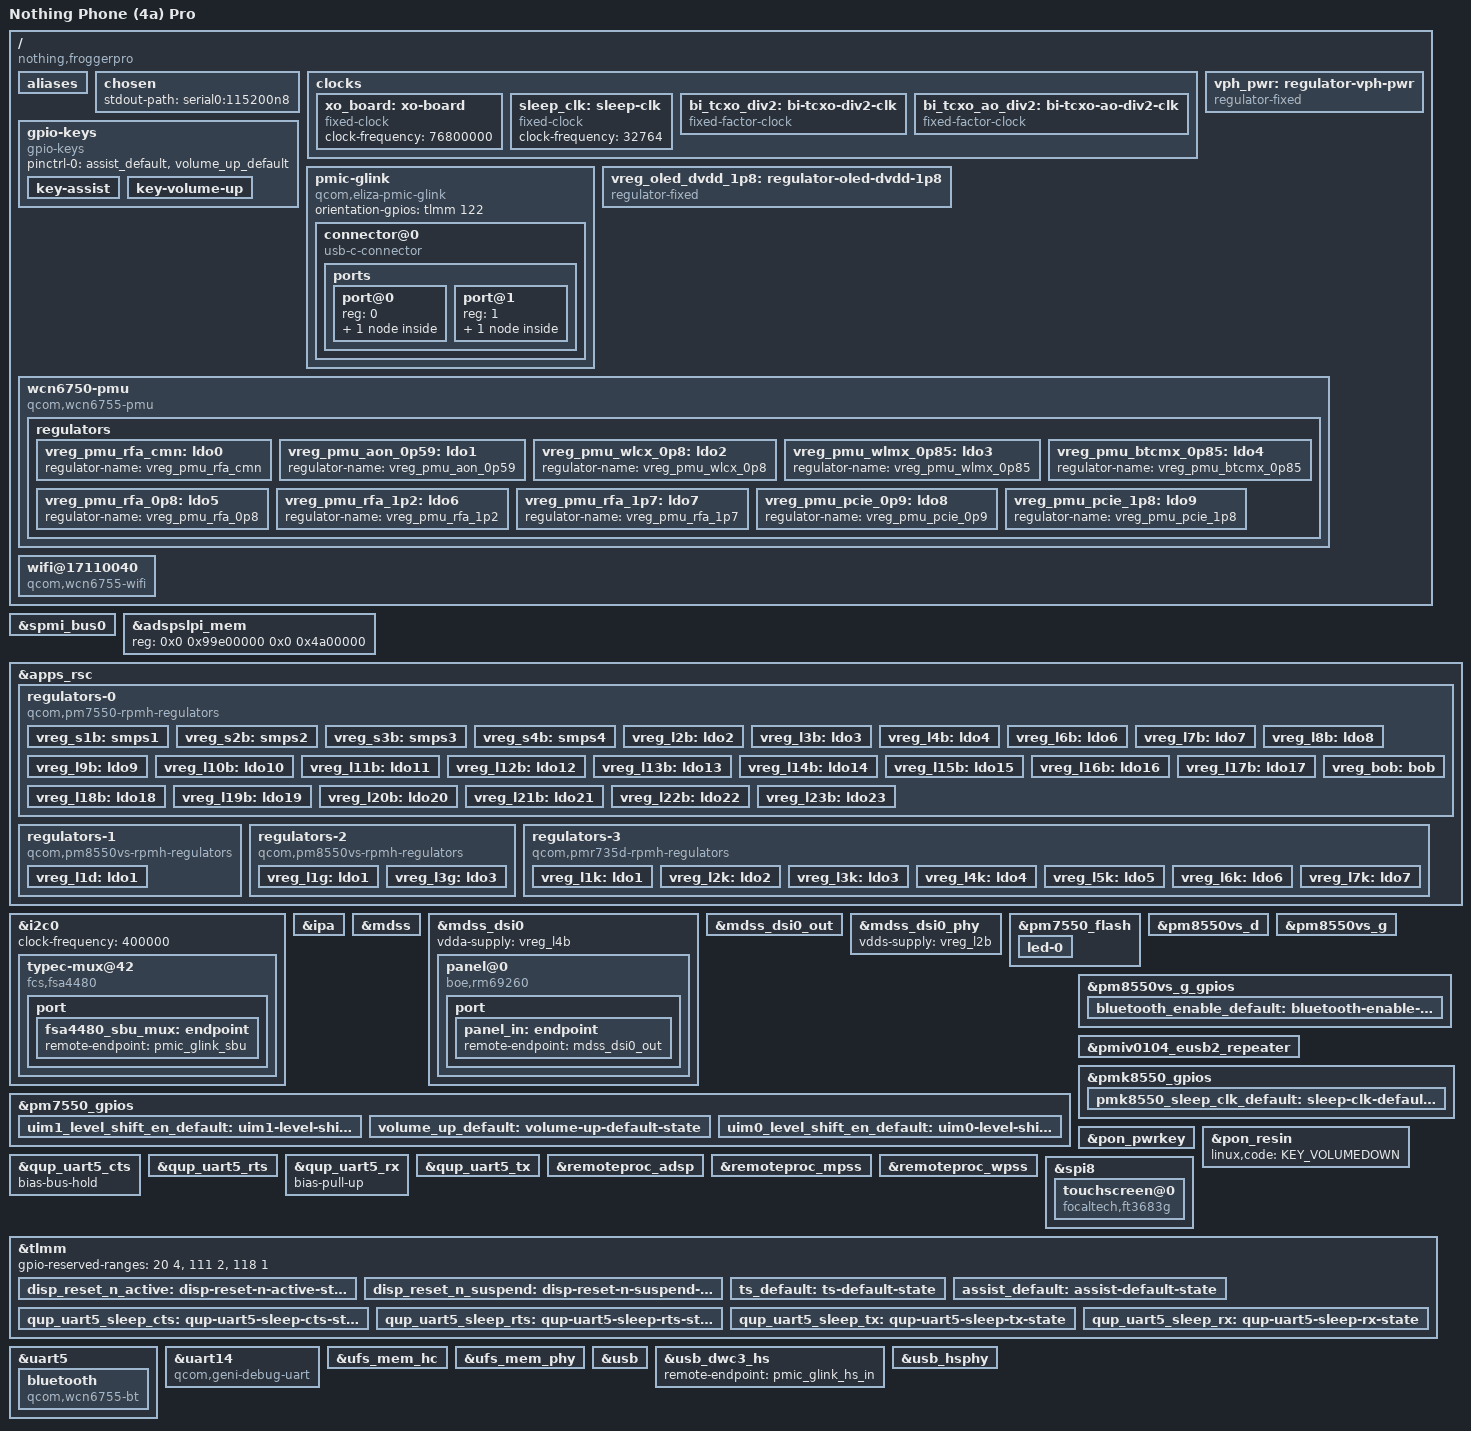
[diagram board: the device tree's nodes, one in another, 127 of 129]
// SPDX-License-Identifier: BSD-3-Clause

/dts-v1/;

#define PMIV0104_SID 7

#include <dt-bindings/arm/qcom,ids.h>
#include <dt-bindings/gpio/gpio.h>
#include <dt-bindings/leds/common.h>
#include <dt-bindings/pinctrl/qcom,pmic-gpio.h>
#include <dt-bindings/regulator/qcom,rpmh-regulator.h>

#include "eliza.dtsi"

spmi_bus: &spmi_bus0 {};

#include "pm7550.dtsi"
#include "pm8550vs.dtsi"
#include "pmk8550.dtsi"
#include "pmiv0104.dtsi" /* PMIV0102 */
#include "pmr735d_a.dtsi"

/ {
	model = "Nothing Phone (4a) Pro";
	compatible = "nothing,froggerpro", "qcom,eliza";
	chassis-type = "handset";
	qcom,board-id = <QCOM_BOARD_ID_QRD 0>;
	qcom,msm-id = <QCOM_ID_SM7750 0x10000>;

	aliases {
		serial0 = &uart14;
		serial1 = &uart5;
	};

	chosen {
		stdout-path = "serial0:115200n8";
	};

	clocks {
		xo_board: xo-board {
			compatible = "fixed-clock";
			clock-frequency = <76800000>;
			#clock-cells = <0>;
		};

		sleep_clk: sleep-clk {
			compatible = "fixed-clock";
			clock-frequency = <32764>;
			#clock-cells = <0>;
		};

		bi_tcxo_div2: bi-tcxo-div2-clk {
			compatible = "fixed-factor-clock";
			#clock-cells = <0>;

			clocks = <&rpmhcc RPMH_CXO_CLK>;
			clock-mult = <1>;
			clock-div = <2>;
		};

		bi_tcxo_ao_div2: bi-tcxo-ao-div2-clk {
			compatible = "fixed-factor-clock";
			#clock-cells = <0>;

			clocks = <&rpmhcc RPMH_CXO_CLK_A>;
			clock-mult = <1>;
			clock-div = <2>;
		};
	};

	gpio-keys {
		compatible = "gpio-keys";

		pinctrl-0 = <&assist_default>, <&volume_up_default>;
		pinctrl-names = "default";

		key-assist {
			gpios = <&tlmm 34 GPIO_ACTIVE_LOW>;
			label = "Assistant";
			linux,code = <KEY_LEFTMETA>;
		};

		key-volume-up {
			gpios = <&pm7550_gpios 6 GPIO_ACTIVE_LOW>;
			label = "Volume Up";
			linux,code = <KEY_VOLUMEUP>;
		};
	};

	pmic-glink {
		compatible = "qcom,eliza-pmic-glink",
			     "qcom,sm8550-pmic-glink",
			     "qcom,pmic-glink";
		#address-cells = <1>;
		#size-cells = <0>;
		orientation-gpios = <&tlmm 122 GPIO_ACTIVE_HIGH>;

		connector@0 {
			compatible = "usb-c-connector";
			reg = <0>;

			power-role = "dual";
			data-role = "dual";

			ports {
				#address-cells = <1>;
				#size-cells = <0>;

				port@0 {
					reg = <0>;

					pmic_glink_hs_in: endpoint {
						remote-endpoint = <&usb_dwc3_hs>;
					};
				};

				port@1 {
					reg = <1>;

					pmic_glink_sbu: endpoint {
						remote-endpoint = <&fsa4480_sbu_mux>;
					};
				};
			};
		};
	};

	vreg_oled_dvdd_1p8: regulator-oled-dvdd-1p8 {
		compatible = "regulator-fixed";
		regulator-name = "oled_dvdd_1p8";
		regulator-min-microvolt = <1800000>;
		regulator-max-microvolt = <1800000>;

		gpio = <&tlmm 108 GPIO_ACTIVE_HIGH>;
		enable-active-high;

		vin-supply = <&vph_pwr>;

		regulator-boot-on;
	};

	vph_pwr: regulator-vph-pwr {
		compatible = "regulator-fixed";

		regulator-name = "vph_pwr";
		regulator-min-microvolt = <3700000>;
		regulator-max-microvolt = <3700000>;

		regulator-always-on;
		regulator-boot-on;
	};

	wcn6750-pmu {
		compatible = "qcom,wcn6755-pmu", "qcom,wcn6750-pmu";

		vddaon-supply = <&vreg_s3b>;
		vddasd-supply = <&vreg_l7b>;
		vddio-supply = <&vreg_l11b>;
		vddpmu-supply = <&vreg_s3b>;
		vddrfa0p8-supply = <&vreg_s3b>;
		vddrfa1p2-supply = <&vreg_s2b>;
		vddrfa1p7-supply = <&vreg_s1b>;
		vddrfa2p2-supply = <&vreg_s4b>;

		bt-enable-gpios = <&pm8550vs_g_gpios 4 GPIO_ACTIVE_HIGH>;

		clocks = <&rpmhcc RPMH_RF_CLK1>;

		pinctrl-0 = <&bluetooth_enable_default>, <&pmk8550_sleep_clk_default>;
		pinctrl-names = "default";

		regulators {
			vreg_pmu_rfa_cmn: ldo0 {
				regulator-name = "vreg_pmu_rfa_cmn";
			};

			vreg_pmu_aon_0p59: ldo1 {
				regulator-name = "vreg_pmu_aon_0p59";
			};

			vreg_pmu_wlcx_0p8: ldo2 {
				regulator-name = "vreg_pmu_wlcx_0p8";
			};

			vreg_pmu_wlmx_0p85: ldo3 {
				regulator-name = "vreg_pmu_wlmx_0p85";
			};

			vreg_pmu_btcmx_0p85: ldo4 {
				regulator-name = "vreg_pmu_btcmx_0p85";
			};

			vreg_pmu_rfa_0p8: ldo5 {
				regulator-name = "vreg_pmu_rfa_0p8";
			};

			vreg_pmu_rfa_1p2: ldo6 {
				regulator-name = "vreg_pmu_rfa_1p2";
			};

			vreg_pmu_rfa_1p7: ldo7 {
				regulator-name = "vreg_pmu_rfa_1p7";
			};

			vreg_pmu_pcie_0p9: ldo8 {
				regulator-name = "vreg_pmu_pcie_0p9";
			};

			vreg_pmu_pcie_1p8: ldo9 {
				regulator-name = "vreg_pmu_pcie_1p8";
			};
		};
	};

	wifi@17110040 {
		compatible = "qcom,wcn6755-wifi", "qcom,wcn6750-wifi";
		reg = <0x0 0x17110040 0x0 0x0>;

		vddaon-supply = <&vreg_pmu_aon_0p59>;

		iommus = <&apps_smmu 0x1480 0x1>;

		interrupts = <GIC_SPI 768 IRQ_TYPE_EDGE_RISING>,
			     <GIC_SPI 769 IRQ_TYPE_EDGE_RISING>,
			     <GIC_SPI 770 IRQ_TYPE_EDGE_RISING>,
			     <GIC_SPI 771 IRQ_TYPE_EDGE_RISING>,
			     <GIC_SPI 772 IRQ_TYPE_EDGE_RISING>,
			     <GIC_SPI 773 IRQ_TYPE_EDGE_RISING>,
			     <GIC_SPI 774 IRQ_TYPE_EDGE_RISING>,
			     <GIC_SPI 775 IRQ_TYPE_EDGE_RISING>,
			     <GIC_SPI 776 IRQ_TYPE_EDGE_RISING>,
			     <GIC_SPI 777 IRQ_TYPE_EDGE_RISING>,
			     <GIC_SPI 778 IRQ_TYPE_EDGE_RISING>,
			     <GIC_SPI 779 IRQ_TYPE_EDGE_RISING>,
			     <GIC_SPI 780 IRQ_TYPE_EDGE_RISING>,
			     <GIC_SPI 781 IRQ_TYPE_EDGE_RISING>,
			     <GIC_SPI 782 IRQ_TYPE_EDGE_RISING>,
			     <GIC_SPI 783 IRQ_TYPE_EDGE_RISING>,
			     <GIC_SPI 784 IRQ_TYPE_EDGE_RISING>,
			     <GIC_SPI 785 IRQ_TYPE_EDGE_RISING>,
			     <GIC_SPI 786 IRQ_TYPE_EDGE_RISING>,
			     <GIC_SPI 787 IRQ_TYPE_EDGE_RISING>,
			     <GIC_SPI 788 IRQ_TYPE_EDGE_RISING>,
			     <GIC_SPI 789 IRQ_TYPE_EDGE_RISING>,
			     <GIC_SPI 790 IRQ_TYPE_EDGE_RISING>,
			     <GIC_SPI 791 IRQ_TYPE_EDGE_RISING>,
			     <GIC_SPI 792 IRQ_TYPE_EDGE_RISING>,
			     <GIC_SPI 793 IRQ_TYPE_EDGE_RISING>,
			     <GIC_SPI 794 IRQ_TYPE_EDGE_RISING>,
			     <GIC_SPI 795 IRQ_TYPE_EDGE_RISING>,
			     <GIC_SPI 796 IRQ_TYPE_EDGE_RISING>,
			     <GIC_SPI 797 IRQ_TYPE_EDGE_RISING>,
			     <GIC_SPI 798 IRQ_TYPE_EDGE_RISING>,
			     <GIC_SPI 799 IRQ_TYPE_EDGE_RISING>;

		qcom,calibration-variant = "Nothing_Phone_4a_Pro";
		qcom,rproc = <&remoteproc_wpss>;
		qcom,smem-states = <&smp2p_wlan_out 0>;
		qcom,smem-state-names = "wlan-smp2p-out";
	};
};

&adspslpi_mem {
	reg = <0x0 0x99e00000 0x0 0x4a00000>;
};

&apps_rsc {
	regulators-0 {
		compatible = "qcom,pm7550-rpmh-regulators";

		vdd-l1-supply = <&vreg_s3b>;
		vdd-l2-l3-supply = <&vreg_s3b>;
		vdd-l4-l5-supply = <&vreg_s2b>;
		vdd-l6-supply = <&vreg_s2b>;
		vdd-l7-supply = <&vreg_s1b>;
		vdd-l8-supply = <&vreg_s1b>;
		vdd-l9-l10-supply = <&vreg_s1b>;
		vdd-l11-supply = <&vreg_s1b>;
		vdd-l12-l14-supply = <&vreg_bob>;
		vdd-l13-l16-supply = <&vreg_bob>;
		vdd-l15-l17-l18-l19-l20-l21-l22-l23-supply = <&vreg_bob>;
		vdd-s1-supply = <&vph_pwr>;
		vdd-s2-supply = <&vph_pwr>;
		vdd-s3-supply = <&vph_pwr>;
		vdd-s4-supply = <&vph_pwr>;
		vdd-s5-supply = <&vph_pwr>;
		vdd-s6-supply = <&vph_pwr>;

		vdd-bob-supply = <&vph_pwr>;

		qcom,pmic-id = "b";

		vreg_s1b: smps1 {
			regulator-name = "vreg_s1b";
			regulator-min-microvolt = <1856000>;
			regulator-max-microvolt = <2040000>;
			regulator-initial-mode = <RPMH_REGULATOR_MODE_HPM>;
		};

		vreg_s2b: smps2 {
			regulator-name = "vreg_s2b";
			regulator-min-microvolt = <1256000>;
			regulator-max-microvolt = <1408000>;
			regulator-initial-mode = <RPMH_REGULATOR_MODE_HPM>;
		};

		vreg_s3b: smps3 {
			regulator-name = "vreg_s3b";
			regulator-min-microvolt = <920000>;
			regulator-max-microvolt = <1040000>;
			regulator-initial-mode = <RPMH_REGULATOR_MODE_HPM>;
		};

		vreg_s4b: smps4 {
			regulator-name = "vreg_s4b";
			regulator-min-microvolt = <2156000>;
			regulator-max-microvolt = <2600000>;
			regulator-initial-mode = <RPMH_REGULATOR_MODE_HPM>;
		};

		vreg_l2b: ldo2 {
			regulator-name = "vreg_l2b";
			regulator-min-microvolt = <720000>;
			regulator-max-microvolt = <950000>;
			regulator-initial-mode = <RPMH_REGULATOR_MODE_HPM>;
		};

		vreg_l3b: ldo3 {
			regulator-name = "vreg_l3b";
			regulator-min-microvolt = <880000>;
			regulator-max-microvolt = <912000>;
			regulator-initial-mode = <RPMH_REGULATOR_MODE_HPM>;
		};

		vreg_l4b: ldo4 {
			regulator-name = "vreg_l4b";
			regulator-min-microvolt = <1200000>;
			regulator-max-microvolt = <1320000>;
			regulator-initial-mode = <RPMH_REGULATOR_MODE_HPM>;
		};

		vreg_l6b: ldo6 {
			regulator-name = "vreg_l6b";
			regulator-min-microvolt = <912000>;
			regulator-max-microvolt = <958000>;
			regulator-initial-mode = <RPMH_REGULATOR_MODE_HPM>;
		};

		vreg_l7b: ldo7 {
			regulator-name = "vreg_l7b";
			regulator-min-microvolt = <1800000>;
			regulator-max-microvolt = <2000000>;
			regulator-initial-mode = <RPMH_REGULATOR_MODE_HPM>;
		};

		vreg_l8b: ldo8 {
			regulator-name = "vreg_l8b";
			regulator-min-microvolt = <1800000>;
			regulator-max-microvolt = <2000000>;
			regulator-initial-mode = <RPMH_REGULATOR_MODE_HPM>;
		};

		vreg_l9b: ldo9 {
			regulator-name = "vreg_l9b";
			regulator-min-microvolt = <756000>;
			regulator-max-microvolt = <816000>;
			regulator-initial-mode = <RPMH_REGULATOR_MODE_HPM>;
		};

		vreg_l10b: ldo10 {
			regulator-name = "vreg_l10b";
			regulator-min-microvolt = <866000>;
			regulator-max-microvolt = <958000>;
			regulator-initial-mode = <RPMH_REGULATOR_MODE_HPM>;
		};

		vreg_l11b: ldo11 {
			regulator-name = "vreg_l11b";
			regulator-min-microvolt = <1800000>;
			regulator-max-microvolt = <2000000>;
			regulator-initial-mode = <RPMH_REGULATOR_MODE_HPM>;
		};

		vreg_l12b: ldo12 {
			regulator-name = "vreg_l12b";
			regulator-min-microvolt = <2504000>;
			regulator-max-microvolt = <3300000>;
			regulator-initial-mode = <RPMH_REGULATOR_MODE_HPM>;
		};

		vreg_l13b: ldo13 {
			regulator-name = "vreg_l13b";
			regulator-min-microvolt = <2700000>;
			regulator-max-microvolt = <3300000>;
			regulator-initial-mode = <RPMH_REGULATOR_MODE_HPM>;
		};

		vreg_l14b: ldo14 {
			regulator-name = "vreg_l14b";
			regulator-min-microvolt = <2650000>;
			regulator-max-microvolt = <2940000>;
			regulator-initial-mode = <RPMH_REGULATOR_MODE_HPM>;
		};

		vreg_l15b: ldo15 {
			regulator-name = "vreg_l15b";
			regulator-min-microvolt = <1620000>;
			regulator-max-microvolt = <3300000>;
			regulator-initial-mode = <RPMH_REGULATOR_MODE_HPM>;
		};

		vreg_l16b: ldo16 {
			regulator-name = "vreg_l16b";
			regulator-min-microvolt = <2900000>;
			regulator-max-microvolt = <3544000>;
			regulator-initial-mode = <RPMH_REGULATOR_MODE_HPM>;
		};

		vreg_l17b: ldo17 {
			regulator-name = "vreg_l17b";
			regulator-min-microvolt = <3104000>;
			regulator-max-microvolt = <3544000>;
			regulator-initial-mode = <RPMH_REGULATOR_MODE_HPM>;
		};

		vreg_l18b: ldo18 {
			regulator-name = "vreg_l18b";
			regulator-min-microvolt = <1600000>;
			regulator-max-microvolt = <3544000>;
			regulator-initial-mode = <RPMH_REGULATOR_MODE_HPM>;
		};

		vreg_l19b: ldo19 {
			regulator-name = "vreg_l19b";
			regulator-min-microvolt = <3000000>;
			regulator-max-microvolt = <3544000>;
			regulator-initial-mode = <RPMH_REGULATOR_MODE_HPM>;
		};

		vreg_l20b: ldo20 {
			regulator-name = "vreg_l20b";
			regulator-min-microvolt = <1504000>;
			regulator-max-microvolt = <3544000>;
			regulator-initial-mode = <RPMH_REGULATOR_MODE_HPM>;
		};

		vreg_l21b: ldo21 {
			regulator-name = "vreg_l21b";
			regulator-min-microvolt = <1504000>;
			regulator-max-microvolt = <3544000>;
			regulator-initial-mode = <RPMH_REGULATOR_MODE_HPM>;
		};

		vreg_l22b: ldo22 {
			regulator-name = "vreg_l22b";
			regulator-min-microvolt = <3304000>;
			regulator-max-microvolt = <3304000>;
			regulator-initial-mode = <RPMH_REGULATOR_MODE_HPM>;
		};

		vreg_l23b: ldo23 {
			regulator-name = "vreg_l23b";
			regulator-min-microvolt = <1650000>;
			regulator-max-microvolt = <3544000>;
			regulator-initial-mode = <RPMH_REGULATOR_MODE_HPM>;
		};

		vreg_bob: bob {
			regulator-name = "vreg_bob";
			regulator-min-microvolt = <3296000>;
			regulator-max-microvolt = <3960000>;
			regulator-initial-mode = <RPMH_REGULATOR_MODE_HPM>;
		};
	};

	regulators-1 {
		compatible = "qcom,pm8550vs-rpmh-regulators";

		vdd-l1-supply = <&vreg_s2b>;

		qcom,pmic-id = "d";

		vreg_l1d: ldo1 {
			regulator-name = "vreg_l1d";
			regulator-min-microvolt = <1200000>;
			regulator-max-microvolt = <2000000>;
			regulator-initial-mode = <RPMH_REGULATOR_MODE_HPM>;
		};
	};

	regulators-2 {
		compatible = "qcom,pm8550vs-rpmh-regulators";

		vdd-l1-supply = <&vreg_s2b>;
		vdd-l3-supply = <&vreg_s2b>;

		qcom,pmic-id = "g";

		vreg_l1g: ldo1 {
			regulator-name = "vreg_l1g";
			regulator-min-microvolt = <1800000>;
			regulator-max-microvolt = <1800000>;
			regulator-initial-mode = <RPMH_REGULATOR_MODE_HPM>;
		};

		vreg_l3g: ldo3 {
			regulator-name = "vreg_l3g";
			regulator-min-microvolt = <1200000>;
			regulator-max-microvolt = <1304000>;
			regulator-initial-mode = <RPMH_REGULATOR_MODE_HPM>;
		};

	};

	regulators-3 {
		compatible = "qcom,pmr735d-rpmh-regulators";

		vdd-l1-l2-l5-supply = <&vreg_s3b>;
		vdd-l3-l4-supply = <&vreg_s2b>;
		vdd-l6-supply = <&vreg_s1b>;
		vdd-l7-supply = <&vreg_s3b>;

		qcom,pmic-id = "k";

		vreg_l1k: ldo1 {
			regulator-name = "vreg_l1k";
			regulator-min-microvolt = <806000>;
			regulator-max-microvolt = <912000>;
			regulator-initial-mode = <RPMH_REGULATOR_MODE_HPM>;
		};

		vreg_l2k: ldo2 {
			regulator-name = "vreg_l2k";
			regulator-min-microvolt = <920000>;
			regulator-max-microvolt = <969000>;
			regulator-initial-mode = <RPMH_REGULATOR_MODE_HPM>;
		};

		vreg_l3k: ldo3 {
			regulator-name = "vreg_l3k";
			regulator-min-microvolt = <1080000>;
			regulator-max-microvolt = <1350000>;
			regulator-initial-mode = <RPMH_REGULATOR_MODE_HPM>;
		};

		vreg_l4k: ldo4 {
			regulator-name = "vreg_l4k";
			regulator-min-microvolt = <960000>;
			regulator-max-microvolt = <1200000>;
			regulator-initial-mode = <RPMH_REGULATOR_MODE_HPM>;
		};

		vreg_l5k: ldo5 {
			regulator-name = "vreg_l5k";
			regulator-min-microvolt = <866000>;
			regulator-max-microvolt = <931000>;
			regulator-initial-mode = <RPMH_REGULATOR_MODE_HPM>;
		};

		vreg_l6k: ldo6 {
			regulator-name = "vreg_l6k";
			regulator-min-microvolt = <1100000>;
			regulator-max-microvolt = <2000000>;
			regulator-initial-mode = <RPMH_REGULATOR_MODE_HPM>;
		};

		vreg_l7k: ldo7 {
			regulator-name = "vreg_l7k";
			regulator-min-microvolt = <880000>;
			regulator-max-microvolt = <950000>;
			regulator-initial-mode = <RPMH_REGULATOR_MODE_HPM>;
		};
	};
};

&i2c0 {
	clock-frequency = <400000>;

	status = "okay";

	typec-mux@42 {
		compatible = "fcs,fsa4480";
		reg = <0x42>;

		vcc-supply = <&vph_pwr>;

		mode-switch;
		orientation-switch;

		port {
			fsa4480_sbu_mux: endpoint {
				remote-endpoint = <&pmic_glink_sbu>;
			};
		};
	};
};

&ipa {
	firmware-name = "qcom/eliza/nothing/froggerpro/ipa_fws.mbn";
	memory-region = <&ipa_fw_mem>;

	qcom,gsi-loader = "self";

	status = "okay";
};

&mdss {
	status = "okay";
};

&mdss_dsi0 {
	vdda-supply = <&vreg_l4b>;

	status = "okay";

	panel@0 {
		compatible = "boe,rm69260";
		reg = <0>;

		reset-gpios = <&tlmm 12 GPIO_ACTIVE_LOW>;

		vci-supply = <&vreg_l19b>;
		dvdd-supply = <&vreg_oled_dvdd_1p8>;
		vddio-supply = <&vreg_l8b>;

		pinctrl-0 = <&disp_reset_n_active>;
		pinctrl-1 = <&disp_reset_n_suspend>;
		pinctrl-names = "default", "sleep";

		port {
			panel_in: endpoint {
				remote-endpoint = <&mdss_dsi0_out>;
			};
		};
	};
};

&mdss_dsi0_out {
	data-lanes = <0 1 2 3>;
	remote-endpoint = <&panel_in>;
};

&mdss_dsi0_phy {
	vdds-supply = <&vreg_l2b>;

	status = "okay";
};

&pm7550_flash {
	status = "okay";

	led-0 {
		function = LED_FUNCTION_FLASH;
		color = <LED_COLOR_ID_WHITE>;
		led-sources = <1>, <4>;
		led-max-microamp = <350000>;
		flash-max-microamp = <1500000>;
		flash-max-timeout-us = <400000>;
	};
};

&pm7550_gpios {
	uim1_level_shift_en_default: uim1-level-shift-en-default {
		pins = "gpio2";
		function = PMIC_GPIO_FUNC_NORMAL;
		power-source = <1>;
		bias-disable;
		input-disable;
		output-high;
	};

	volume_up_default: volume-up-default-state {
		pins = "gpio6";
		function = PMIC_GPIO_FUNC_NORMAL;
		input-enable;
		power-source = <1>;
		bias-pull-up;
	};

	uim0_level_shift_en_default: uim0-level-shift-en-default {
		pins = "gpio11";
		function = PMIC_GPIO_FUNC_NORMAL;
		power-source = <1>;
		bias-disable;
		input-disable;
		output-high;
	};
};

&pm8550vs_d {
	status = "okay";
};

&pm8550vs_g {
	status = "okay";
};

&pm8550vs_g_gpios {
	bluetooth_enable_default: bluetooth-enable-default-state {
		pins = "gpio4";
		function = PMIC_GPIO_FUNC_NORMAL;
		input-disable;
		output-enable;
		bias-disable;
		power-source = <1>;
	};
};

&pmiv0104_eusb2_repeater {
	vdd18-supply = <&vreg_l7b>;
	vdd3-supply = <&vreg_l17b>;

	qcom,tune-usb2-amplitude = /bits/ 8 <0xd>;
	qcom,tune-usb2-preem = /bits/ 8 <0x7>;
	qcom,squelch-detector-bp = <(-2000)>;
};

&pmk8550_gpios {
	pmk8550_sleep_clk_default: sleep-clk-default-state {
		pins = "gpio3";
		function = PMIC_GPIO_FUNC_FUNC1;
		input-disable;
		output-enable;
		bias-disable;
		power-source = <0>;
	};
};

&pon_pwrkey {
	status = "okay";
};

&pon_resin {
	linux,code = <KEY_VOLUMEDOWN>;

	status = "okay";
};

&qup_uart5_cts {
	/*
	 * Configure a bias-bus-hold on CTS to lower power
	 * usage when Bluetooth is turned off. Bus hold will
	 * maintain a low power state regardless of whether
	 * the Bluetooth module drives the pin in either
	 * direction or leaves the pin fully unpowered.
	 */
	bias-bus-hold;
};

&qup_uart5_rts {
	/* We'll drive RTS, so no pull */
	drive-strength = <2>;
	bias-disable;
};

&qup_uart5_rx {
	/*
	 * Configure a pull-up on RX. This is needed to avoid
	 * garbage data when the TX pin of the Bluetooth module is
	 * in tri-state (module powered off or not driving the
	 * signal yet).
	 */
	bias-pull-up;
};

&qup_uart5_tx {
	/* We'll drive TX, so no pull */
	drive-strength = <2>;
	bias-disable;
};

&remoteproc_adsp {
	firmware-name = "qcom/eliza/nothing/froggerpro/adsp.mbn",
			"qcom/eliza/nothing/froggerpro/adsp_dtb.mbn";

	status = "okay";
};

&remoteproc_mpss {
	pinctrl-0 = <&uim0_level_shift_en_default
		     &uim1_level_shift_en_default>;
	pinctrl-names = "default";

	firmware-name = "qcom/eliza/nothing/froggerpro/modem.mbn",
			"qcom/eliza/nothing/froggerpro/modem_dtb.mbn";

	status = "okay";
};

&remoteproc_wpss {
	firmware-name = "qcom/eliza/nothing/froggerpro/wpss.mbn";

	status = "okay";
};

&spi8 {
	status = "okay";

	touchscreen@0 {
		compatible = "focaltech,ft3683g";
		reg = <0>;

		pinctrl-0 = <&ts_default>;
		pinctrl-names = "default";

		reset-gpios = <&tlmm 16 GPIO_ACTIVE_LOW>;

		interrupt-parent = <&tlmm>;
		interrupts = <13 IRQ_TYPE_EDGE_FALLING>;
		spi-max-frequency = <12000000>;

		vci-supply = <&vreg_l22b>;
		vddio-supply = <&vreg_l1g>;

		touchscreen-size-x = <1260>;
		touchscreen-size-y = <2800>;
	};
};

&tlmm {
	gpio-reserved-ranges = <20 4>,
			       <111 2>, /* WCN UART1 */
			       <118 1>;

	disp_reset_n_active: disp-reset-n-active-state {
		pins = "gpio12";
		function = "gpio";
		drive-strength = <8>;
		bias-disable;
	};

	disp_reset_n_suspend: disp-reset-n-suspend-state {
		pins = "gpio12";
		function = "gpio";
		drive-strength = <2>;
		bias-pull-down;
	};

	ts_default: ts-default-state {
		pins = "gpio13", "gpio16";
		function = "gpio";
		drive-strength = <8>;
		bias-pull-up;
	};

	assist_default: assist-default-state {
		pins = "gpio34";
		function = "gpio";
		bias-pull-up;
	};

	qup_uart5_sleep_cts: qup-uart5-sleep-cts-state {
		pins = "gpio132";
		function = "gpio";
		/*
		 * Configure a bias-bus-hold on CTS to lower power
		 * usage when Bluetooth is turned off. Bus hold will
		 * maintain a low power state regardless of whether
		 * the Bluetooth module drives the pin in either
		 * direction or leaves the pin fully unpowered.
		 */
		bias-bus-hold;
	};

	qup_uart5_sleep_rts: qup-uart5-sleep-rts-state {
		pins = "gpio133";
		function = "gpio";
		/*
		 * Configure pull-down on RTS. As RTS is active low
		 * signal, pull it low to indicate the BT SoC that it
		 * can wakeup the system anytime from suspend state by
		 * pulling RX low (by sending wakeup bytes).
		 */
		bias-pull-down;
	};

	qup_uart5_sleep_tx: qup-uart5-sleep-tx-state {
		pins = "gpio134";
		function = "gpio";
		/*
		 * Configure pull-up on TX when it isn't actively driven
		 * to prevent BT SoC from receiving garbage during sleep.
		 */
		bias-pull-up;
	};

	qup_uart5_sleep_rx: qup-uart5-sleep-rx-state {
		pins = "gpio135";
		function = "gpio";
		/*
		 * Configure a pull-up on RX. This is needed to avoid
		 * garbage data when the TX pin of the Bluetooth module
		 * is floating which may cause spurious wakeups.
		 */
		bias-pull-up;
	};
};

&uart5 {
	/delete-property/ interrupts;
	interrupts-extended = <&intc GIC_SPI 358 IRQ_TYPE_LEVEL_HIGH>,
			      <&tlmm 135 IRQ_TYPE_EDGE_FALLING>;

	pinctrl-1 = <&qup_uart5_sleep_cts>,
		     <&qup_uart5_sleep_rts>,
		     <&qup_uart5_sleep_tx>,
		     <&qup_uart5_sleep_rx>;
	pinctrl-names = "default",
			"sleep";

	status = "okay";

	bluetooth {
		compatible = "qcom,wcn6755-bt", "qcom,wcn6750-bt";

		vddaon-supply = <&vreg_pmu_aon_0p59>;
		vddbtcmx-supply = <&vreg_pmu_btcmx_0p85>;
		vddrfa0p8-supply = <&vreg_pmu_rfa_0p8>;
		vddrfa1p2-supply = <&vreg_pmu_rfa_1p2>;
		vddrfa1p7-supply = <&vreg_pmu_rfa_1p7>;
		vddrfacmn-supply = <&vreg_pmu_rfa_cmn>;
	};
};

&uart14 {
	compatible = "qcom,geni-debug-uart";

	status = "okay";
};

&ufs_mem_hc {
	reset-gpios = <&tlmm 185 GPIO_ACTIVE_LOW>;

	vcc-supply = <&vreg_l12b>;
	vcc-max-microamp = <1300000>;
	vccq-supply = <&vreg_l1d>;
	vccq-max-microamp = <1200000>;

	status = "okay";
};

&ufs_mem_phy {
	vdda-phy-supply = <&vreg_l6b>;
	vdda-pll-supply = <&vreg_l4b>;

	status = "okay";
};

&usb {
	maximum-speed = "high-speed";
	phys = <&usb_hsphy>;
	phy-names = "usb2-phy";

	/* USB 2.0 only, HW does not support USB 3.x */
	qcom,select-utmi-as-pipe-clk;

	status = "okay";
};

&usb_dwc3_hs {
	remote-endpoint = <&pmic_glink_hs_in>;
};

&usb_hsphy {
	vdd-supply = <&vreg_l7k>;
	vdda12-supply = <&vreg_l4b>;

	phys = <&pmiv0104_eusb2_repeater>;

	status = "okay";
};
